AUTOSAR XML (schema 4-2-2)
package /AUTOLIV/SoftwareComponents/BMM
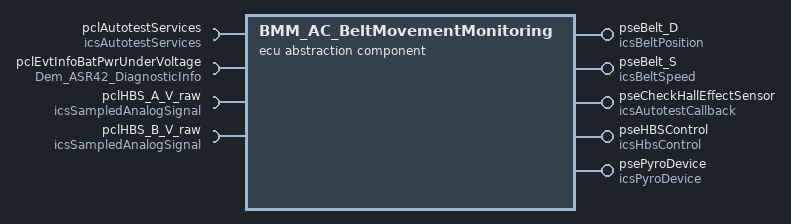
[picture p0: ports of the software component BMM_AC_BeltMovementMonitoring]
  ecu abstraction sw component type BMM_AC_BeltMovementMonitoring: category=IO_HW_ABS
    4 x require port:
      pclAutotestServices: required-com-specs=[GetTestResult, GetLastCriticalAutotestID], required-interface=icsAutotestServices
      pclEvtInfoBatPwrUnderVoltage: required-interface=Dem_ASR42_DiagnosticInfo
        required-com-specs:
          GetEventStatus
          GetEventFailed
          GetEventTested
          GetDTCOfEvent
          GetFaultDetectionCounter
          GetEventFreezeFrameData
          GetEventExtendedDataRecord
      pclHBS_A_V_raw: required-com-specs=[Get, Get_2ms, Get_10ms, Get_20ms, Get_100ms], required-interface=icsSampledAnalogSignal
      pclHBS_B_V_raw: required-com-specs=[Get, Get_2ms, Get_10ms, Get_20ms, Get_100ms], required-interface=icsSampledAnalogSignal
    5 x provide port:
      pseBelt_D: provided-interface=icsBeltPosition
        provided-com-specs:
          operation=GetFromT0_mm, queue-length=1
          operation=GetFromT0_deg, queue-length=1
          operation=GetRange_mm, queue-length=1
          operation=GetRange_deg, queue-length=1
          operation=GetFromMinPos_deg, queue-length=1
          operation=GetFromMinPos_mm, queue-length=1
      pseBelt_S: provided-com-specs=[{operation=GetSpeed_mm_s, queue-length=1}, {operation=GetSpeed_deg_s, queue-length=1}], provided-interface=icsBeltSpeed
      pseCheckHallEffectSensor: server-com-spec{operation=AutotestCallback, queue-length=1}, provided-interface=icsAutotestCallback
      pseHBSControl: provided-com-specs=[{operation=DisableHBSMonitoring, queue-length=1}, {operation=EnableHBSMonitoring, queue-length=1}], provided-interface=icsHbsControl
      psePyroDevice: server-com-spec{operation=GetPyroActivationStatus, queue-length=1}, provided-interface=icsPyroDevice
